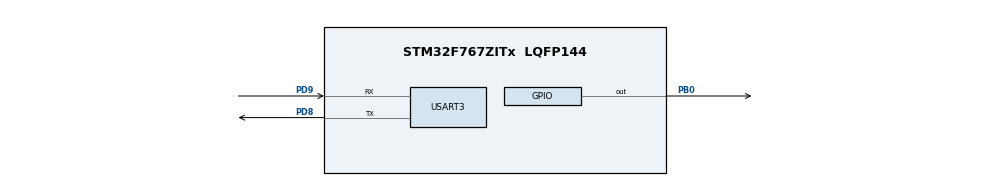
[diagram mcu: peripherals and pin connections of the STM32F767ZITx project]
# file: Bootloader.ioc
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Mcu.Family=STM32F7
Mcu.Name=STM32F767ZITx
Mcu.Package=LQFP144
NVIC.PriorityGroup=NVIC_PRIORITYGROUP_4
PB0.Signal=GPIO_Output
PD8.Mode=Asynchronous
PD8.Signal=USART3_TX
PD9.Mode=Asynchronous
PD9.Signal=USART3_RX
ProjectManager.HeapSize=0x200
ProjectManager.StackSize=0x400
ProjectManager.TargetToolchain=STM32CubeIDE
RCC.HSE_VALUE=25000000
RCC.HSI_VALUE=16000000
RCC.LSE_VALUE=32768
RCC.USBFreq_Value=96000000
RCC.VCOOutputFreq_Value=192000000
USART3.VirtualMode-Asynchronous=VM_ASYNC
board=custom

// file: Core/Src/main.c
/* USER CODE BEGIN Header */
/**
  ******************************************************************************
  * @file           : main.c
  * @brief          : Main program body
  ******************************************************************************
  * @attention
  *
  * <h2><center>&copy; Copyright (c) 2021 STMicroelectronics.
  * All rights reserved.</center></h2>
  *
  * This software component is licensed by ST under BSD 3-Clause license,
  * the "License"; You may not use this file except in compliance with the
  * License. You may obtain a copy of the License at:
  *                        opensource.org/licenses/BSD-3-Clause
  *
  ******************************************************************************
  */
/* USER CODE END Header */
#include "main.h"
#include "xmodem.h"
#include "flash.h"

/* USER CODE BEGIN Includes */
#include <stdio.h>
/* USER CODE END Includes */

UART_HandleTypeDef huart3;

void SystemClock_Config(void);
static void MX_GPIO_Init(void);
static void MX_USART3_UART_Init(void);

int main(void)
{

  /* MCU Configuration--------------------------------------------------------*/

  /* Reset of all peripherals, Initializes the Flash interface and the Systick. */
  HAL_Init();

  /* Configure the system clock */
  SystemClock_Config();

  /* Initialize all configured peripherals */
  MX_GPIO_Init();
  MX_USART3_UART_Init();
  /* USER CODE BEGIN 2 */
  /* Send welcome message on startup. */
  uart_transmit_str((uint8_t*)"\n\r================================\n\r");
  uart_transmit_str((uint8_t*)"Created By Oubrahim\n\r");
  uart_transmit_str((uint8_t*)"UART Bootloader\n\r");
  uart_transmit_str((uint8_t*)"================================\n\r\n\r");
  /* USER CODE END 2 */

  /* Infinite loop */
  while (1)
  {
	    HAL_GPIO_WritePin(GPIOB, GPIO_PIN_0, GPIO_PIN_SET );    //Green LED ON
	    /* Ask for new data and start the Xmodem protocol. */
	    uart_transmit_str((uint8_t*)"Please send a new binary file.\n\r");
	    xmodem_receive();
	    /* We only exit the xmodem protocol, if there are any errors.
	     * In that case, notify the user and start over. */
	    uart_transmit_str((uint8_t*)"\n\rFailed... Please try again.\n\r");
  }
}

void SystemClock_Config(void)
{
  RCC_OscInitTypeDef RCC_OscInitStruct = {0};
  RCC_ClkInitTypeDef RCC_ClkInitStruct = {0};
  RCC_PeriphCLKInitTypeDef PeriphClkInitStruct = {0};

  /** Configure the main internal regulator output voltage
  */
  __HAL_RCC_PWR_CLK_ENABLE();
  __HAL_PWR_VOLTAGESCALING_CONFIG(PWR_REGULATOR_VOLTAGE_SCALE3);
  /** Initializes the RCC Oscillators according to the specified parameters
  * in the RCC_OscInitTypeDef structure.
  */
  RCC_OscInitStruct.OscillatorType = RCC_OSCILLATORTYPE_HSI;
  RCC_OscInitStruct.HSIState = RCC_HSI_ON;
  RCC_OscInitStruct.HSICalibrationValue = RCC_HSICALIBRATION_DEFAULT;
  RCC_OscInitStruct.PLL.PLLState = RCC_PLL_NONE;
  if (HAL_RCC_OscConfig(&RCC_OscInitStruct) != HAL_OK)
  {
    Error_Handler();
  }
  /** Initializes the CPU, AHB and APB buses clocks
  */
  RCC_ClkInitStruct.ClockType = RCC_CLOCKTYPE_HCLK|RCC_CLOCKTYPE_SYSCLK
                              |RCC_CLOCKTYPE_PCLK1|RCC_CLOCKTYPE_PCLK2;
  RCC_ClkInitStruct.SYSCLKSource = RCC_SYSCLKSOURCE_HSI;
  RCC_ClkInitStruct.AHBCLKDivider = RCC_SYSCLK_DIV1;
  RCC_ClkInitStruct.APB1CLKDivider = RCC_HCLK_DIV1;
  RCC_ClkInitStruct.APB2CLKDivider = RCC_HCLK_DIV1;

  if (HAL_RCC_ClockConfig(&RCC_ClkInitStruct, FLASH_LATENCY_0) != HAL_OK)
  {
    Error_Handler();
  }
  PeriphClkInitStruct.PeriphClockSelection = RCC_PERIPHCLK_USART3;
  PeriphClkInitStruct.Usart3ClockSelection = RCC_USART3CLKSOURCE_PCLK1;
  if (HAL_RCCEx_PeriphCLKConfig(&PeriphClkInitStruct) != HAL_OK)
  {
    Error_Handler();
  }
}

static void MX_USART3_UART_Init(void)
{

  huart3.Instance = USART3;
  huart3.Init.BaudRate = 115200;
  huart3.Init.WordLength = UART_WORDLENGTH_8B;
  huart3.Init.StopBits = UART_STOPBITS_1;
  huart3.Init.Parity = UART_PARITY_NONE;
  huart3.Init.Mode = UART_MODE_TX_RX;
  huart3.Init.HwFlowCtl = UART_HWCONTROL_NONE;
  huart3.Init.OverSampling = UART_OVERSAMPLING_16;
  huart3.Init.OneBitSampling = UART_ONE_BIT_SAMPLE_DISABLE;
  huart3.AdvancedInit.AdvFeatureInit = UART_ADVFEATURE_NO_INIT;
  if (HAL_UART_Init(&huart3) != HAL_OK)
  {
    Error_Handler();
  }

}

static void MX_GPIO_Init(void)
{
  GPIO_InitTypeDef GPIO_InitStruct = {0};

  /* GPIO Ports Clock Enable */
  __HAL_RCC_GPIOB_CLK_ENABLE();
  __HAL_RCC_GPIOD_CLK_ENABLE();

  /*Configure GPIO pin Output Level */
  HAL_GPIO_WritePin(GPIOB, GPIO_PIN_0, GPIO_PIN_RESET);

  /*Configure GPIO pin : PB0 */
  GPIO_InitStruct.Pin = GPIO_PIN_0;
  GPIO_InitStruct.Mode = GPIO_MODE_OUTPUT_PP;
  GPIO_InitStruct.Pull = GPIO_NOPULL;
  GPIO_InitStruct.Speed = GPIO_SPEED_FREQ_LOW;
  HAL_GPIO_Init(GPIOB, &GPIO_InitStruct);

}

/* USER CODE BEGIN 4 */
/**
  * @brief Print the characters to UART (printf).
  * @retval int
  */
#ifdef __GNUC__
  /* With GCC, small printf (option LD Linker->Libraries->Small printf
     set to 'Yes') calls __io_putchar() */
int __io_putchar(int ch)
#else
int fputc(int ch, FILE *f)
#endif /* __GNUC__ */
{
  /* Place your implementation of fputc here */
  /* e.g. write a character to the UART3 and Loop until the end of transmission */
  HAL_UART_Transmit(&huart3, (uint8_t *)&ch, 1, HAL_MAX_DELAY);

  return ch;
}

/**
  * @brief Jump to application from the Bootloader
  * @retval None
  */
/* USER CODE END 4 */

void Error_Handler(void)
{
  __disable_irq();
  while (1)
  {
  }
}

/************************ (C) COPYRIGHT STMicroelectronics *****END OF FILE****/
